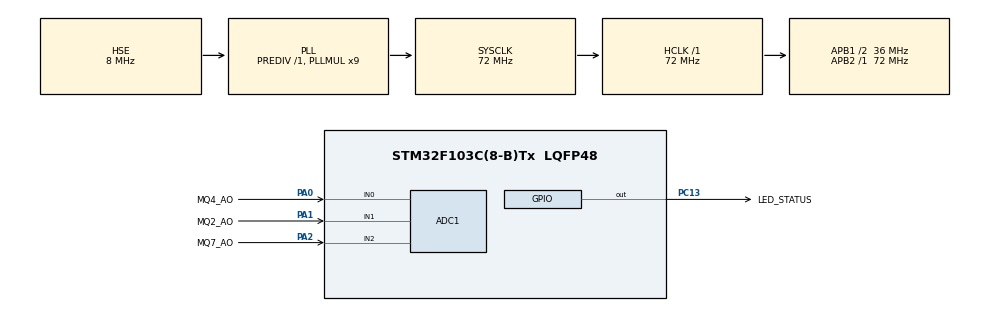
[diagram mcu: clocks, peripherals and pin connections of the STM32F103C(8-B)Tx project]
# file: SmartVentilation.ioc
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ADC1.Channel-1\#ChannelRegularConversion=ADC_CHANNEL_0
ADC1.Channel-2\#ChannelRegularConversion=ADC_CHANNEL_1
ADC1.Channel-3\#ChannelRegularConversion=ADC_CHANNEL_2
ADC1.ContinuousConvMode=ENABLE
ADC1.NbrOfConversion=3
ADC1.NbrOfConversionFlag=1
ADC1.Rank-1\#ChannelRegularConversion=1
ADC1.Rank-2\#ChannelRegularConversion=2
ADC1.Rank-3\#ChannelRegularConversion=3
ADC1.SamplingTime-1\#ChannelRegularConversion=ADC_SAMPLETIME_55CYCLES_5
ADC1.SamplingTime-2\#ChannelRegularConversion=ADC_SAMPLETIME_55CYCLES_5
ADC1.SamplingTime-3\#ChannelRegularConversion=ADC_SAMPLETIME_55CYCLES_5
ADC1.master=1
Mcu.Family=STM32F1
Mcu.Name=STM32F103C(8-B)Tx
Mcu.Package=LQFP48
NVIC.PriorityGroup=NVIC_PRIORITYGROUP_4
PA0-WKUP.GPIO_Label=MQ4_AO
PA0-WKUP.Signal=ADCx_IN0
PA1.GPIO_Label=MQ2_AO
PA1.Signal=ADCx_IN1
PA13.Mode=Serial_Wire
PA13.Signal=SYS_JTMS-SWDIO
PA14.Mode=Serial_Wire
PA14.Signal=SYS_JTCK-SWCLK
PA2.GPIO_Label=MQ7_AO
PA2.Signal=ADCx_IN2
PC13-TAMPER-RTC.GPIO_Label=LED_STATUS
PC13-TAMPER-RTC.Signal=GPIO_Output
PD0-OSC_IN.Mode=HSE-External-Oscillator
PD0-OSC_IN.Signal=RCC_OSC_IN
PD1-OSC_OUT.Mode=HSE-External-Oscillator
PD1-OSC_OUT.Signal=RCC_OSC_OUT
ProjectManager.HeapSize=0x200
ProjectManager.StackSize=0x400
ProjectManager.TargetToolchain=MDK-ARM V5.32
RCC.ADCPresc=RCC_ADCPCLK2_DIV6
RCC.AHBFreq_Value=72000000
RCC.APB1CLKDivider=RCC_HCLK_DIV2
RCC.APB1Freq_Value=36000000
RCC.APB1TimFreq_Value=72000000
RCC.APB2Freq_Value=72000000
RCC.APB2TimFreq_Value=72000000
RCC.HCLKFreq_Value=72000000
RCC.PLLMUL=RCC_PLL_MUL9
RCC.PLLSourceVirtual=RCC_PLLSOURCE_HSE
RCC.SYSCLKFreq_VALUE=72000000
RCC.SYSCLKSource=RCC_SYSCLKSOURCE_PLLCLK
RCC.USBFreq_Value=72000000
SH.ADCx_IN0.0=ADC1_IN0,IN0
SH.ADCx_IN1.0=ADC1_IN1,IN1
SH.ADCx_IN2.0=ADC1_IN2,IN2
board=custom

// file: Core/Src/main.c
/* USER CODE BEGIN Header */
/**
  ******************************************************************************
  * @file           : main.c
  * @brief          : Main program body
  ******************************************************************************
  * @attention
  *
  * Copyright (c) 2025 STMicroelectronics.
  * All rights reserved.
  *
  * This software is licensed under terms that can be found in the LICENSE file
  * in the root directory of this software component.
  * If no LICENSE file comes with this software, it is provided AS-IS.
  *
  ******************************************************************************
  */
/* USER CODE END Header */
#include "main.h"
#include "adc.h"
#include "gpio.h"

/* USER CODE BEGIN Includes */
#include "adc_driver.h"
#include <stdio.h>
#include "filter.h"

/* USER CODE END Includes */

/* USER CODE BEGIN PV */
ADC_RawData_t adc_raw;
SensorData_t sensor_data;
char uart_buffer[100];

/* USER CODE END PV */

void SystemClock_Config(void);

int main(void)
{

  /* MCU Configuration--------------------------------------------------------*/

  /* Reset of all peripherals, Initializes the Flash interface and the Systick. */
  HAL_Init();

  /* Configure the system clock */
  SystemClock_Config();

  /* Initialize all configured peripherals */
  MX_GPIO_Init();
  MX_ADC1_Init();
  /* USER CODE BEGIN 2 */
  ADC_Driver_Init();  // 初始化ADC驱动

  /* USER CODE END 2 */

  /* Infinite loop */
  while (1)
  {

    /* USER CODE BEGIN 3 */

////    // LED闪烁测试
////    HAL_GPIO_WritePin(GPIOC, GPIO_PIN_13, GPIO_PIN_SET);   // 点亮LED
////    HAL_Delay(2000);                                        // 延时500ms
////    HAL_GPIO_WritePin(GPIOC, GPIO_PIN_13, GPIO_PIN_RESET); // 熄灭LED
////    HAL_Delay(2000);                                        // 延时500ms
//
//    // LED闪烁 (保持原来的测试)
//    HAL_GPIO_TogglePin(GPIOC, GPIO_PIN_13);
//
//    // 读取所有传感器
//    ADC_ReadAllSensors(&adc_raw);
//
//    // 转换为PPM浓度
//    ADC_ConvertToPPM(&adc_raw, &sensor_data);
//	  HAL_Delay(1000);  // 1秒采集一次

//    HAL_GPIO_TogglePin(GPIOC, GPIO_PIN_13);		//翻转 GPIO 引脚的状态

    // 使用带滤波的读取函数
    ADC_ReadAllSensors_Filtered(&adc_raw);

    // 转换为PPM
    ADC_ConvertToPPM(&adc_raw, &sensor_data);

    HAL_Delay(100);  // 改为100ms采样一次（更快）

    // 打印调试信息 (需要配置串口才能看到，暂时先存储数据)
    // sprintf(uart_buffer, "MQ4:%d MQ2:%d MQ7:%d\r\n",
    //         adc_raw.mq4_raw, adc_raw.mq2_raw, adc_raw.mq7_raw);

  }
  /* USER CODE END 3 */
}

void SystemClock_Config(void)
{
  RCC_OscInitTypeDef RCC_OscInitStruct = {0};
  RCC_ClkInitTypeDef RCC_ClkInitStruct = {0};
  RCC_PeriphCLKInitTypeDef PeriphClkInit = {0};

  /** Initializes the RCC Oscillators according to the specified parameters
  * in the RCC_OscInitTypeDef structure.
  */
  RCC_OscInitStruct.OscillatorType = RCC_OSCILLATORTYPE_HSE;
  RCC_OscInitStruct.HSEState = RCC_HSE_ON;
  RCC_OscInitStruct.HSEPredivValue = RCC_HSE_PREDIV_DIV1;
  RCC_OscInitStruct.HSIState = RCC_HSI_ON;
  RCC_OscInitStruct.PLL.PLLState = RCC_PLL_ON;
  RCC_OscInitStruct.PLL.PLLSource = RCC_PLLSOURCE_HSE;
  RCC_OscInitStruct.PLL.PLLMUL = RCC_PLL_MUL9;
  if (HAL_RCC_OscConfig(&RCC_OscInitStruct) != HAL_OK)
  {
    Error_Handler();
  }

  /** Initializes the CPU, AHB and APB buses clocks
  */
  RCC_ClkInitStruct.ClockType = RCC_CLOCKTYPE_HCLK|RCC_CLOCKTYPE_SYSCLK
                              |RCC_CLOCKTYPE_PCLK1|RCC_CLOCKTYPE_PCLK2;
  RCC_ClkInitStruct.SYSCLKSource = RCC_SYSCLKSOURCE_PLLCLK;
  RCC_ClkInitStruct.AHBCLKDivider = RCC_SYSCLK_DIV1;
  RCC_ClkInitStruct.APB1CLKDivider = RCC_HCLK_DIV2;
  RCC_ClkInitStruct.APB2CLKDivider = RCC_HCLK_DIV1;

  if (HAL_RCC_ClockConfig(&RCC_ClkInitStruct, FLASH_LATENCY_2) != HAL_OK)
  {
    Error_Handler();
  }
  PeriphClkInit.PeriphClockSelection = RCC_PERIPHCLK_ADC;
  PeriphClkInit.AdcClockSelection = RCC_ADCPCLK2_DIV6;
  if (HAL_RCCEx_PeriphCLKConfig(&PeriphClkInit) != HAL_OK)
  {
    Error_Handler();
  }
}

void Error_Handler(void)
{
  __disable_irq();
  while (1)
  {
  }
}
